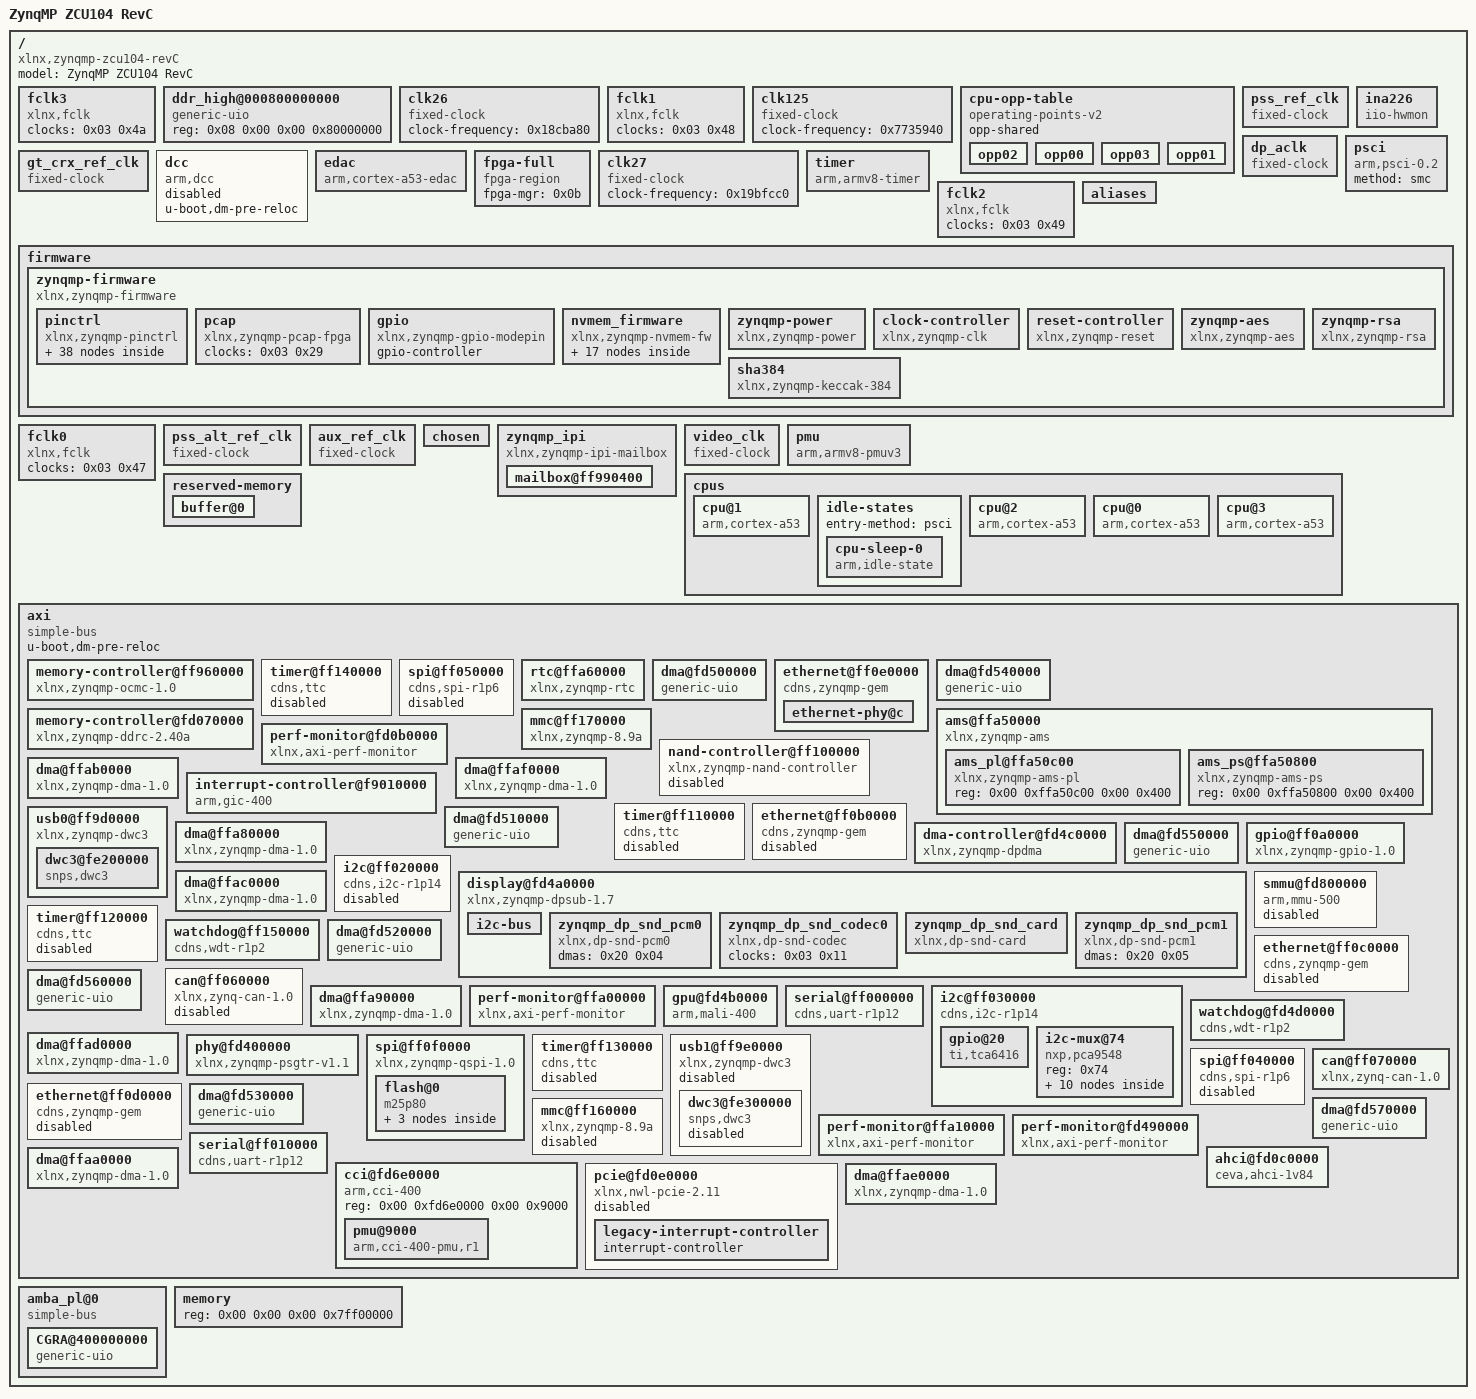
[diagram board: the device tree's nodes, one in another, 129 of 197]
/dts-v1/;

/ {
	#address-cells = <0x02>;
	model = "ZynqMP ZCU104 RevC";
	#size-cells = <0x02>;
	compatible = "xlnx,zynqmp-zcu104-revC\0xlnx,zynqmp-zcu104\0xlnx,zynqmp";

	fclk3 {
		clocks = <0x03 0x4a>;
		compatible = "xlnx,fclk";
		status = "okay";
		phandle = <0x85>;
	};

	ddr_high@000800000000 {
		compatible = "generic-uio";
		reg = <0x08 0x00 0x00 0x80000000>;
	};

	clk26 {
		#clock-cells = <0x00>;
		clock-frequency = <0x18cba80>;
		compatible = "fixed-clock";
		phandle = <0x17>;
	};

	fclk1 {
		clocks = <0x03 0x48>;
		compatible = "xlnx,fclk";
		status = "okay";
		phandle = <0x83>;
	};

	clk125 {
		#clock-cells = <0x00>;
		clock-frequency = <0x7735940>;
		compatible = "fixed-clock";
		phandle = <0x16>;
	};

	cpu-opp-table {
		opp-shared;
		compatible = "operating-points-v2";
		phandle = <0x01>;

		opp02 {
			opp-microvolt = <0xf4240>;
			opp-hz = <0x00 0x17d783fc>;
			clock-latency-ns = <0x7a120>;
		};

		opp00 {
			opp-microvolt = <0xf4240>;
			opp-hz = <0x00 0x47868bf4>;
			clock-latency-ns = <0x7a120>;
		};

		opp03 {
			opp-microvolt = <0xf4240>;
			opp-hz = <0x00 0x11e1a2fd>;
			clock-latency-ns = <0x7a120>;
		};

		opp01 {
			opp-microvolt = <0xf4240>;
			opp-hz = <0x00 0x23c345fa>;
			clock-latency-ns = <0x7a120>;
		};
	};

	pss_ref_clk {
		u-boot,dm-pre-reloc;
		#clock-cells = <0x00>;
		clock-frequency = <0x1fca055>;
		compatible = "fixed-clock";
		phandle = <0x06>;
	};

	ina226 {
		io-channels = <0x25 0x00 0x25 0x01 0x25 0x02 0x25 0x03>;
		compatible = "iio-hwmon";
	};

	dp_aclk {
		clock-accuracy = <0x64>;
		#clock-cells = <0x00>;
		clock-frequency = <0x5f5e100>;
		compatible = "fixed-clock";
		phandle = <0x21>;
	};

	gt_crx_ref_clk {
		u-boot,dm-pre-reloc;
		#clock-cells = <0x00>;
		clock-frequency = <0x66ff300>;
		compatible = "fixed-clock";
		phandle = <0x0a>;
	};

	psci {
		method = "smc";
		compatible = "arm,psci-0.2";
	};

	dcc {
		u-boot,dm-pre-reloc;
		compatible = "arm,dcc";
		status = "disabled";
		phandle = <0x2b>;
	};

	edac {
		compatible = "arm,cortex-a53-edac";
	};

	fpga-full {
		fpga-mgr = <0x0b>;
		#address-cells = <0x02>;
		#size-cells = <0x02>;
		compatible = "fpga-region";
		ranges;
		phandle = <0x42>;
	};

	clk27 {
		#clock-cells = <0x00>;
		clock-frequency = <0x19bfcc0>;
		compatible = "fixed-clock";
		phandle = <0x18>;
	};

	timer {
		interrupts = <0x01 0x0d 0xf08 0x01 0x0e 0xf08 0x01 0x0b 0xf08 0x01 0x0a 0xf08>;
		interrupt-parent = <0x04>;
		compatible = "arm,armv8-timer";
	};

	fclk2 {
		clocks = <0x03 0x49>;
		compatible = "xlnx,fclk";
		status = "okay";
		phandle = <0x84>;
	};

	aliases {
		ethernet0 = "/axi/ethernet@ff0e0000";
		spi0 = "/axi/spi@ff0f0000";
		serial1 = "/axi/serial@ff010000";
		i2c0 = "/axi/i2c@ff030000";
		serial0 = "/axi/serial@ff000000";
	};

	firmware {

		zynqmp-firmware {
			method = "smc";
			u-boot,dm-pre-reloc;
			#power-domain-cells = <0x01>;
			compatible = "xlnx,zynqmp-firmware";
			phandle = <0x0c>;

			pinctrl {
				compatible = "xlnx,zynqmp-pinctrl";
				status = "okay";
				phandle = <0x3f>;

				usb0-default {
					phandle = <0x1f>;

					mux {
						function = "usb0";
						groups = "usb0_0_grp";
					};

					conf {
						drive-strength = <0x0c>;
						slew-rate = <0x01>;
						groups = "usb0_0_grp";
						power-source = <0x01>;
					};

					conf-tx {
						pins = "MIO54\0MIO56\0MIO57\0MIO58\0MIO59\0MIO60\0MIO61\0MIO62\0MIO63";
						bias-disable;
					};

					conf-rx {
						pins = "MIO52\0MIO53\0MIO55";
						bias-high-impedance;
					};
				};

				sdhci1-default {
					phandle = <0x1b>;

					mux-cd {
						function = "sdio1_cd";
						groups = "sdio1_cd_0_grp";
					};

					conf-cd {
						bias-high-impedance;
						slew-rate = <0x01>;
						bias-pull-up;
						groups = "sdio1_cd_0_grp";
						power-source = <0x01>;
					};

					mux {
						function = "sdio1";
						groups = "sdio1_0_grp";
					};

					conf {
						drive-strength = <0x0c>;
						bias-disable;
						slew-rate = <0x01>;
						groups = "sdio1_0_grp";
						power-source = <0x01>;
					};
				};

				i2c1-default {
					phandle = <0x11>;

					mux {
						function = "i2c1";
						groups = "i2c1_4_grp";
					};

					conf {
						drive-strength = <0x0c>;
						slew-rate = <0x01>;
						bias-pull-up;
						groups = "i2c1_4_grp";
						power-source = <0x01>;
					};
				};

				uart1-default {
					phandle = <0x1d>;

					mux {
						function = "uart1";
						groups = "uart1_5_grp";
					};

					conf {
						drive-strength = <0x0c>;
						slew-rate = <0x01>;
						groups = "uart1_5_grp";
						power-source = <0x01>;
					};

					conf-tx {
						pins = "MIO20";
						bias-disable;
					};

					conf-rx {
						pins = "MIO21";
						bias-high-impedance;
					};
				};

				can1-default {
					phandle = <0x0d>;

					mux {
						function = "can1";
						groups = "can1_6_grp";
					};

					conf {
						drive-strength = <0x0c>;
						slew-rate = <0x01>;
						groups = "can1_6_grp";
						power-source = <0x01>;
					};

					conf-tx {
						pins = "MIO24";
						bias-disable;
					};

					conf-rx {
						pins = "MIO25";
						bias-high-impedance;
					};
				};

				i2c1-gpio {
					phandle = <0x12>;

					mux {
						function = "gpio0";
						groups = "gpio0_16_grp\0gpio0_17_grp";
					};

					conf {
						drive-strength = <0x0c>;
						slew-rate = <0x01>;
						groups = "gpio0_16_grp\0gpio0_17_grp";
						power-source = <0x01>;
					};
				};

				gem3-default {
					phandle = <0x10>;

					mux {
						function = "ethernet3";
						groups = "ethernet3_0_grp";
					};

					conf {
						drive-strength = <0x0c>;
						slew-rate = <0x01>;
						groups = "ethernet3_0_grp";
						power-source = <0x01>;
					};

					mux-mdio {
						function = "mdio3";
						groups = "mdio3_0_grp";
					};

					conf-mdio {
						bias-disable;
						slew-rate = <0x01>;
						groups = "mdio3_0_grp";
						power-source = <0x01>;
					};

					conf-tx {
						pins = "MIO64\0MIO65\0MIO66\0MIO67\0MIO68\0MIO69";
						bias-disable;
						low-power-enable;
					};

					conf-rx {
						low-power-disable;
						pins = "MIO70\0MIO71\0MIO72\0MIO73\0MIO74\0MIO75";
						bias-high-impedance;
					};
				};

				uart0-default {
					phandle = <0x1c>;

					mux {
						function = "uart0";
						groups = "uart0_4_grp";
					};

					conf {
						drive-strength = <0x0c>;
						slew-rate = <0x01>;
						groups = "uart0_4_grp";
						power-source = <0x01>;
					};

					conf-tx {
						pins = "MIO19";
						bias-disable;
					};

					conf-rx {
						pins = "MIO18";
						bias-high-impedance;
					};
				};
			};

			pcap {
				clock-names = "ref_clk";
				clocks = <0x03 0x29>;
				compatible = "xlnx,zynqmp-pcap-fpga";
				phandle = <0x0b>;
			};

			gpio {
				gpio-controller;
				compatible = "xlnx,zynqmp-gpio-modepin";
				phandle = <0x1e>;
				#gpio-cells = <0x02>;
			};

			nvmem_firmware {
				#address-cells = <0x01>;
				#size-cells = <0x01>;
				compatible = "xlnx,zynqmp-nvmem-fw";

				efuse_pufmisc@54 {
					reg = <0x54 0x04>;
					phandle = <0x39>;
				};

				efuse_ppk1hash@d0 {
					reg = <0xd0 0x30>;
					phandle = <0x3d>;
				};

				efuse_usr3@2c {
					reg = <0x2c 0x04>;
					phandle = <0x32>;
				};

				efuse_dna@c {
					reg = <0x0c 0x0c>;
					phandle = <0x2e>;
				};

				efuse_ppk0hash@a0 {
					reg = <0xa0 0x30>;
					phandle = <0x3c>;
				};

				efuse_usr1@24 {
					reg = <0x24 0x04>;
					phandle = <0x30>;
				};

				efuse_usr6@38 {
					reg = <0x38 0x04>;
					phandle = <0x35>;
				};

				efuse_spkid@5c {
					reg = <0x5c 0x04>;
					phandle = <0x3b>;
				};

				efuse_chash@50 {
					reg = <0x50 0x04>;
					phandle = <0x38>;
				};

				efuse_usr4@30 {
					reg = <0x30 0x04>;
					phandle = <0x33>;
				};

				efuse_miscusr@40 {
					reg = <0x40 0x04>;
					phandle = <0x37>;
				};

				efuse_usr7@3c {
					reg = <0x3c 0x04>;
					phandle = <0x36>;
				};

				efuse_usr2@28 {
					reg = <0x28 0x04>;
					phandle = <0x31>;
				};

				efuse_usr0@20 {
					reg = <0x20 0x04>;
					phandle = <0x2f>;
				};

				soc_revision@0 {
					reg = <0x00 0x04>;
					phandle = <0x2d>;
				};

				efuse_sec@58 {
					reg = <0x58 0x04>;
					phandle = <0x3a>;
				};

				efuse_usr5@34 {
					reg = <0x34 0x04>;
					phandle = <0x34>;
				};
			};

			zynqmp-power {
				u-boot,dm-pre-reloc;
				interrupts = <0x00 0x23 0x04>;
				interrupt-parent = <0x04>;
				compatible = "xlnx,zynqmp-power";
				phandle = <0x2c>;
				mboxes = <0x05 0x00 0x05 0x01>;
				mbox-names = "tx\0rx";
			};

			clock-controller {
				clock-names = "pss_ref_clk\0video_clk\0pss_alt_ref_clk\0aux_ref_clk\0gt_crx_ref_clk";
				u-boot,dm-pre-reloc;
				clocks = <0x06 0x07 0x08 0x09 0x0a>;
				#clock-cells = <0x01>;
				compatible = "xlnx,zynqmp-clk";
				phandle = <0x03>;
			};

			reset-controller {
				#reset-cells = <0x01>;
				compatible = "xlnx,zynqmp-reset";
				phandle = <0x19>;
			};

			zynqmp-aes {
				compatible = "xlnx,zynqmp-aes";
				phandle = <0x3e>;
			};

			sha384 {
				compatible = "xlnx,zynqmp-keccak-384";
				phandle = <0x40>;
			};

			zynqmp-rsa {
				compatible = "xlnx,zynqmp-rsa";
				phandle = <0x41>;
			};
		};
	};

	fclk0 {
		clocks = <0x03 0x47>;
		compatible = "xlnx,fclk";
		status = "okay";
		phandle = <0x82>;
	};

	pss_alt_ref_clk {
		u-boot,dm-pre-reloc;
		#clock-cells = <0x00>;
		clock-frequency = <0x00>;
		compatible = "fixed-clock";
		phandle = <0x08>;
	};

	aux_ref_clk {
		u-boot,dm-pre-reloc;
		#clock-cells = <0x00>;
		clock-frequency = <0x19bfcc0>;
		compatible = "fixed-clock";
		phandle = <0x09>;
	};

	chosen {
		bootargs = "earlycon clk_ignore_unused cpuidle.off=1 root=/dev/mmcblk0p2 rw rootwait uio_pdrv_genirq.of_id=generic-uio mem=1792M";
		nvmem0 = "/axi/i2c@ff030000/i2c-mux@74/i2c@0/eeprom@54";
		stdout-path = "serial0:115200n8";
	};

	zynqmp_ipi {
		#address-cells = <0x02>;
		xlnx,ipi-id = <0x00>;
		u-boot,dm-pre-reloc;
		interrupts = <0x00 0x23 0x04>;
		#size-cells = <0x02>;
		interrupt-parent = <0x04>;
		compatible = "xlnx,zynqmp-ipi-mailbox";
		ranges;
		phandle = <0x2a>;

		mailbox@ff990400 {
			xlnx,ipi-id = <0x04>;
			reg-names = "local_request_region\0local_response_region\0remote_request_region\0remote_response_region";
			u-boot,dm-pre-reloc;
			#mbox-cells = <0x01>;
			reg = <0x00 0xff9905c0 0x00 0x20 0x00 0xff9905e0 0x00 0x20 0x00 0xff990e80 0x00 0x20 0x00 0xff990ea0 0x00 0x20>;
			phandle = <0x05>;
		};
	};

	video_clk {
		u-boot,dm-pre-reloc;
		#clock-cells = <0x00>;
		clock-frequency = <0x1fc9f08>;
		compatible = "fixed-clock";
		phandle = <0x07>;
	};

	pmu {
		interrupts = <0x00 0x8f 0x04 0x00 0x90 0x04 0x00 0x91 0x04 0x00 0x92 0x04>;
		interrupt-parent = <0x04>;
		compatible = "arm,armv8-pmuv3";
	};

	cpus {
		#address-cells = <0x01>;
		#size-cells = <0x00>;

		cpu@1 {
			cpu-idle-states = <0x02>;
			device_type = "cpu";
			compatible = "arm,cortex-a53";
			reg = <0x01>;
			enable-method = "psci";
			phandle = <0x27>;
			operating-points-v2 = <0x01>;
		};

		idle-states {
			entry-method = "psci";

			cpu-sleep-0 {
				entry-latency-us = <0x12c>;
				local-timer-stop;
				exit-latency-us = <0x258>;
				arm,psci-suspend-param = <0x40000000>;
				compatible = "arm,idle-state";
				phandle = <0x02>;
				min-residency-us = <0x2710>;
			};
		};

		cpu@2 {
			cpu-idle-states = <0x02>;
			device_type = "cpu";
			compatible = "arm,cortex-a53";
			reg = <0x02>;
			enable-method = "psci";
			phandle = <0x28>;
			operating-points-v2 = <0x01>;
		};

		cpu@0 {
			clocks = <0x03 0x0a>;
			cpu-idle-states = <0x02>;
			device_type = "cpu";
			compatible = "arm,cortex-a53";
			reg = <0x00>;
			enable-method = "psci";
			phandle = <0x26>;
			operating-points-v2 = <0x01>;
		};

		cpu@3 {
			cpu-idle-states = <0x02>;
			device_type = "cpu";
			compatible = "arm,cortex-a53";
			reg = <0x03>;
			enable-method = "psci";
			phandle = <0x29>;
			operating-points-v2 = <0x01>;
		};
	};

	__symbols__ {
		efuse_usr0 = "/firmware/zynqmp-firmware/nvmem_firmware/efuse_usr0@20";
		fpd_dma_chan3 = "/axi/dma@fd520000";
		efuse_ppk0hash = "/firmware/zynqmp-firmware/nvmem_firmware/efuse_ppk0hash@a0";
		ams_ps = "/axi/ams@ffa50000/ams_ps@ffa50800";
		nand0 = "/axi/nand-controller@ff100000";
		fclk3 = "/fclk3";
		zynqmp_pcap = "/firmware/zynqmp-firmware/pcap";
		reserved = "/reserved-memory/buffer@0";
		CPU_SLEEP_0 = "/cpus/idle-states/cpu-sleep-0";
		pinctrl_uart0_default = "/firmware/zynqmp-firmware/pinctrl/uart0-default";
		efuse_chash = "/firmware/zynqmp-firmware/nvmem_firmware/efuse_chash@50";
		ipi_mailbox_pmu1 = "/zynqmp_ipi/mailbox@ff990400";
		i2c1 = "/axi/i2c@ff030000";
		fpd_dma_chan1 = "/axi/dma@fd500000";
		efuse_sec = "/firmware/zynqmp-firmware/nvmem_firmware/efuse_sec@58";
		pinctrl_sdhci1_default = "/firmware/zynqmp-firmware/pinctrl/sdhci1-default";
		ttc3 = "/axi/timer@ff140000";
		qspi = "/axi/spi@ff0f0000";
		zynqmp_dp_snd_pcm0 = "/axi/display@fd4a0000/zynqmp_dp_snd_pcm0";
		fclk1 = "/fclk1";
		gpu = "/axi/gpu@fd4b0000";
		spi0 = "/axi/spi@ff040000";
		lpd_dma_chan8 = "/axi/dma@ffaf0000";
		pinctrl_i2c1_default = "/firmware/zynqmp-firmware/pinctrl/i2c1-default";
		efuse_usr7 = "/firmware/zynqmp-firmware/nvmem_firmware/efuse_usr7@3c";
		gpio = "/axi/gpio@ff0a0000";
		zynqmp_clk = "/firmware/zynqmp-firmware/clock-controller";
		usb1 = "/axi/usb1@ff9e0000";
		ttc1 = "/axi/timer@ff120000";
		amba = "/axi";
		efuse_spkid = "/firmware/zynqmp-firmware/nvmem_firmware/efuse_spkid@5c";
		pss_ref_clk = "/pss_ref_clk";
		lpd_dma_chan6 = "/axi/dma@ffad0000";
		efuse_usr5 = "/firmware/zynqmp-firmware/nvmem_firmware/efuse_usr5@34";
		fpd_dma_chan8 = "/axi/dma@fd570000";
		efuse_ppk1hash = "/firmware/zynqmp-firmware/nvmem_firmware/efuse_ppk1hash@d0";
		pinctrl_can1_default = "/firmware/zynqmp-firmware/pinctrl/can1-default";
		CGRA_0 = "/amba_pl@0/CGRA@400000000";
		gem3 = "/axi/ethernet@ff0e0000";
		dp_aclk = "/dp_aclk";
		cpu3 = "/cpus/cpu@3";
		dwc3_0 = "/axi/usb0@ff9d0000/dwc3@fe200000";
		perf_monitor_cci = "/axi/perf-monitor@fd490000";
		clock_8t49n287_2 = "/clk26";
		lpd_dma_chan4 = "/axi/dma@ffab0000";
		efuse_usr3 = "/firmware/zynqmp-firmware/nvmem_firmware/efuse_usr3@2c";
		fpd_dma_chan6 = "/axi/dma@fd550000";
		gt_crx_ref_clk = "/gt_crx_ref_clk";
		gic = "/axi/interrupt-controller@f9010000";
		gem1 = "/axi/ethernet@ff0c0000";
		sata = "/axi/ahci@fd0c0000";
		cpu1 = "/cpus/cpu@1";
		xilinx_ams = "/axi/ams@ffa50000";
		pinctrl_gem3_default = "/firmware/zynqmp-firmware/pinctrl/gem3-default";
		perf_monitor_lpd = "/axi/perf-monitor@ffa10000";
		xlnx_keccak_384 = "/firmware/zynqmp-firmware/sha384";
		uart0 = "/axi/serial@ff000000";
		zynqmp_dp_snd_codec0 = "/axi/display@fd4a0000/zynqmp_dp_snd_codec0";
		dcc = "/dcc";
		lpd_dma_chan2 = "/axi/dma@ffa90000";
		ams_pl = "/axi/ams@ffa50000/ams_pl@ffa50c00";
		efuse_usr1 = "/firmware/zynqmp-firmware/nvmem_firmware/efuse_usr1@24";
		fpd_dma_chan4 = "/axi/dma@fd530000";
		cci = "/axi/cci@fd6e0000";
		perf_monitor_ddr = "/axi/perf-monitor@fd0b0000";
		cpu_opp_table = "/cpu-opp-table";
		can0 = "/axi/can@ff060000";
		tca6416_u97 = "/axi/i2c@ff030000/gpio@20";
		pcie = "/axi/pcie@fd0e0000";
		sdhci0 = "/axi/mmc@ff160000";
		irps5401_43 = "/axi/i2c@ff030000/i2c-mux@74/i2c@2/irps5401@43";
		perf_monitor_ocm = "/axi/perf-monitor@ffa00000";
		watchdog0 = "/axi/watchdog@fd4d0000";
		fpga_full = "/fpga-full";
		fpd_dma_chan2 = "/axi/dma@fd510000";
		zynqmp_firmware = "/firmware/zynqmp-firmware";
		zynqmp_dp_snd_pcm1 = "/axi/display@fd4a0000/zynqmp_dp_snd_pcm1";
		fclk2 = "/fclk2";
		spi1 = "/axi/spi@ff050000";
		xlnx_aes = "/firmware/zynqmp-firmware/zynqmp-aes";
		ocm = "/axi/memory-controller@ff960000";
		pinctrl_i2c1_gpio = "/firmware/zynqmp-firmware/pinctrl/i2c1-gpio";
		eeprom = "/axi/i2c@ff030000/i2c-mux@74/i2c@0/eeprom@54";
		pinctrl_uart1_default = "/firmware/zynqmp-firmware/pinctrl/uart1-default";
		i2c0 = "/axi/i2c@ff020000";
		ttc2 = "/axi/timer@ff130000";
		soc_revision = "/firmware/zynqmp-firmware/nvmem_firmware/soc_revision@0";
		fclk0 = "/fclk0";
		clock_8t49n287_5 = "/clk125";
		pss_alt_ref_clk = "/pss_alt_ref_clk";
		lpd_dma_chan7 = "/axi/dma@ffae0000";
		efuse_usr6 = "/firmware/zynqmp-firmware/nvmem_firmware/efuse_usr6@38";
		efuse_dna = "/firmware/zynqmp-firmware/nvmem_firmware/efuse_dna@c";
		aux_ref_clk = "/aux_ref_clk";
		psgtr = "/axi/phy@fd400000";
		usb0 = "/axi/usb0@ff9d0000";
		amba_pl = "/amba_pl@0";
		xlnx_rsa = "/firmware/zynqmp-firmware/zynqmp-rsa";
		ttc0 = "/axi/timer@ff110000";
		flash0 = "/axi/spi@ff0f0000/flash@0";
		mc = "/axi/memory-controller@fd070000";
		zynqmp_dpsub = "/axi/display@fd4a0000";
		pinctrl0 = "/firmware/zynqmp-firmware/pinctrl";
		dwc3_1 = "/axi/usb1@ff9e0000/dwc3@fe300000";
		clock_8t49n287_3 = "/clk27";
		phy0 = "/axi/ethernet@ff0e0000/ethernet-phy@c";
		lpd_dma_chan5 = "/axi/dma@ffac0000";
		zynqmp_ipi = "/zynqmp_ipi";
		efuse_usr4 = "/firmware/zynqmp-firmware/nvmem_firmware/efuse_usr4@30";
		fpd_dma_chan7 = "/axi/dma@fd560000";
		video_clk = "/video_clk";
		u183 = "/axi/i2c@ff030000/i2c-mux@74/i2c@3/ina226@40";
		gem2 = "/axi/ethernet@ff0d0000";
		efuse_pufmisc = "/firmware/zynqmp-firmware/nvmem_firmware/efuse_pufmisc@54";
		zynqmp_dpdma = "/axi/dma-controller@fd4c0000";
		cpu2 = "/cpus/cpu@2";
		uart1 = "/axi/serial@ff010000";
		efuse_miscusr = "/firmware/zynqmp-firmware/nvmem_firmware/efuse_miscusr@40";
		lpd_dma_chan3 = "/axi/dma@ffaa0000";
		efuse_usr2 = "/firmware/zynqmp-firmware/nvmem_firmware/efuse_usr2@28";
		fpd_dma_chan5 = "/axi/dma@fd540000";
		zynqmp_dp_snd_card0 = "/axi/display@fd4a0000/zynqmp_dp_snd_card";
		zynqmp_power = "/firmware/zynqmp-firmware/zynqmp-power";
		can1 = "/axi/can@ff070000";
		gem0 = "/axi/ethernet@ff0b0000";
		pinctrl_usb0_default = "/firmware/zynqmp-firmware/pinctrl/usb0-default";
		pcie_intc = "/axi/pcie@fd0e0000/legacy-interrupt-controller";
		sdhci1 = "/axi/mmc@ff170000";
		irps5401_44 = "/axi/i2c@ff030000/i2c-mux@74/i2c@2/irps5401@44";
		rtc = "/axi/rtc@ffa60000";
		smmu = "/axi/smmu@fd800000";
		lpd_watchdog = "/axi/watchdog@ff150000";
		modepin_gpio = "/firmware/zynqmp-firmware/gpio";
		cpu0 = "/cpus/cpu@0";
		zynqmp_reset = "/firmware/zynqmp-firmware/reset-controller";
		lpd_dma_chan1 = "/axi/dma@ffa80000";
	};

	reserved-memory {
		#address-cells = <0x02>;
		#size-cells = <0x02>;
		ranges;

		buffer@0 {
			reg = <0x08 0x00 0x00 0x80000000>;
			phandle = <0x88>;
			no-map;
		};
	};

	axi {
		#address-cells = <0x02>;
		u-boot,dm-pre-reloc;
		#size-cells = <0x02>;
		compatible = "simple-bus";
		ranges;
		phandle = <0x43>;

		memory-controller@ff960000 {
			interrupts = <0x00 0x0a 0x04>;
			interrupt-parent = <0x04>;
			compatible = "xlnx,zynqmp-ocmc-1.0";
			reg = <0x00 0xff960000 0x00 0x1000>;
			phandle = <0x64>;
		};

		timer@ff140000 {
			power-domains = <0x0c 0x1b>;
			timer-width = <0x20>;
			interrupts = <0x00 0x2d 0x04 0x00 0x2e 0x04 0x00 0x2f 0x04>;
			clocks = <0x03 0x1f>;
			interrupt-parent = <0x04>;
			compatible = "cdns,ttc";
			status = "disabled";
			reg = <0x00 0xff140000 0x00 0x1000>;
			phandle = <0x74>;
		};

		spi@ff050000 {
			power-domains = <0x0c 0x24>;
			#address-cells = <0x01>;
			clock-names = "ref_clk\0pclk";
			interrupts = <0x00 0x14 0x04>;
			clocks = <0x03 0x3b 0x03 0x1f>;
			#size-cells = <0x00>;
			interrupt-parent = <0x04>;
			compatible = "cdns,spi-r1p6";
			status = "disabled";
			reg = <0x00 0xff050000 0x00 0x1000>;
			phandle = <0x70>;
		};

		rtc@ffa60000 {
			calibration = <0x7fff>;
			interrupts = <0x00 0x1a 0x04 0x00 0x1b 0x04>;
			interrupt-parent = <0x04>;
			compatible = "xlnx,zynqmp-rtc";
			status = "okay";
			interrupt-names = "alarm\0sec";
			reg = <0x00 0xffa60000 0x00 0x100>;
			phandle = <0x6b>;
		};

		dma@fd500000 {
			power-domains = <0x0c 0x2a>;
			iommus = <0x0e 0x14e8>;
			clock-names = "clk_main\0clk_apb";
			interrupts = <0x00 0x7c 0x04>;
			clocks = <0x03 0x13 0x03 0x1f>;
			interrupt-parent = <0x04>;
			xlnx,bus-width = <0x80>;
			compatible = "generic-uio";
			status = "okay";
			#stream-id-cells = <0x01>;
			reg = <0x00 0xfd500000 0x00 0x1000>;
			phandle = <0x47>;
		};

		ethernet@ff0e0000 {
			power-domains = <0x0c 0x20>;
			iommus = <0x0e 0x877>;
			pinctrl-names = "default";
			#address-cells = <0x01>;
			phy-mode = "rgmii-id";
			pinctrl-0 = <0x10>;
			clock-names = "pclk\0hclk\0tx_clk\0rx_clk\0tsu_clk";
			local-mac-address = [00 0a 35 00 9b 24];
			interrupts = <0x00 0x3f 0x04 0x00 0x3f 0x04>;
			clocks = <0x03 0x1f 0x03 0x6b 0x03 0x30 0x03 0x34 0x03 0x2c>;
			#size-cells = <0x00>;
			interrupt-parent = <0x04>;
			compatible = "cdns,zynqmp-gem\0cdns,gem";
			status = "okay";
			#stream-id-cells = <0x01>;
			reg = <0x00 0xff0e0000 0x00 0x1000>;
			phandle = <0x5d>;
			phy-handle = <0x0f>;
			xlnx,ptp-enet-clock = <0x00>;

			ethernet-phy@c {
				ti,dp83867-rxctrl-strap-quirk;
				ti,tx-internal-delay = <0x0a>;
				ti,fifo-depth = <0x01>;
				ti,rx-internal-delay = <0x08>;
				reg = <0x0c>;
				phandle = <0x0f>;
			};
		};

		dma@fd540000 {
			power-domains = <0x0c 0x2a>;
			iommus = <0x0e 0x14ec>;
			clock-names = "clk_main\0clk_apb";
			interrupts = <0x00 0x80 0x04>;
			clocks = <0x03 0x13 0x03 0x1f>;
			interrupt-parent = <0x04>;
			xlnx,bus-width = <0x80>;
			compatible = "generic-uio";
			status = "okay";
			#stream-id-cells = <0x01>;
			reg = <0x00 0xfd540000 0x00 0x1000>;
			phandle = <0x4b>;
		};

		ams@ffa50000 {
			#address-cells = <0x02>;
			reg-names = "ams-base";
			interrupts = <0x00 0x38 0x04>;
			clocks = <0x03 0x46>;
			#io-channel-cells = <0x01>;
			#size-cells = <0x02>;
			interrupt-parent = <0x04>;
			compatible = "xlnx,zynqmp-ams";
			ranges;
			status = "okay";
			interrupt-names = "ams-irq";
			reg = <0x00 0xffa50000 0x00 0x800>;
			phandle = <0x7d>;

			ams_pl@ffa50c00 {
				compatible = "xlnx,zynqmp-ams-pl";
				status = "okay";
				reg = <0x00 0xffa50c00 0x00 0x400>;
				phandle = <0x7f>;
			};

			ams_ps@ffa50800 {
				compatible = "xlnx,zynqmp-ams-ps";
				status = "okay";
				reg = <0x00 0xffa50800 0x00 0x400>;
				phandle = <0x7e>;
			};
		};

		memory-controller@fd070000 {
			interrupts = <0x00 0x70 0x04>;
			interrupt-parent = <0x04>;
			compatible = "xlnx,zynqmp-ddrc-2.40a";
			reg = <0x00 0xfd070000 0x00 0x30000>;
			phandle = <0x58>;
		};

		mmc@ff170000 {
			power-domains = <0x0c 0x28>;
			iommus = <0x0e 0x871>;
			pinctrl-names = "default";
			clock-output-names = "clk_out_sd1\0clk_in_sd1";
			xlnx,mio-bank = <0x01>;
			pinctrl-0 = <0x1b>;
			clock-names = "clk_xin\0clk_ahb";
			u-boot,dm-pre-reloc;
			interrupts = <0x00 0x31 0x04>;
			clocks = <0x03 0x37 0x03 0x1f>;
			#clock-cells = <0x01>;
			xlnx,device_id = <0x01>;
			interrupt-parent = <0x04>;
			clock-frequency = <0xb2d05e0>;
			no-1-8-v;
			compatible = "xlnx,zynqmp-8.9a\0arasan,sdhci-8.9a";
			status = "okay";
			disable-wp;
			#stream-id-cells = <0x01>;
			reg = <0x00 0xff170000 0x00 0x1000>;
			phandle = <0x6e>;
		};

		perf-monitor@fd0b0000 {
			xlnx,metric-count-width = <0x20>;
			xlnx,have-sampled-metric-cnt = <0x01>;
			xlnx,enable-trace = <0x00>;
			xlnx,global-count-width = <0x20>;
			xlnx,enable-event-count = <0x01>;
			interrupts = <0x00 0x7b 0x04>;
			clocks = <0x03 0x1c>;
			xlnx,enable-profile = <0x00>;
			xlnx,metric-count-scale = <0x01>;
			interrupt-parent = <0x04>;
			xlnx,num-monitor-slots = <0x06>;
			compatible = "xlnx,axi-perf-monitor";
			xlnx,num-of-counters = <0x0a>;
			reg = <0x00 0xfd0b0000 0x00 0x10000>;
			phandle = <0x66>;
			xlnx,metrics-sample-count-width = <0x20>;
			xlnx,enable-event-log = <0x00>;
		};

		nand-controller@ff100000 {
			power-domains = <0x0c 0x2c>;
			iommus = <0x0e 0x872>;
			#address-cells = <0x01>;
			clock-names = "controller\0bus";
			interrupts = <0x00 0x0e 0x04>;
			clocks = <0x03 0x3c 0x03 0x1f>;
			#size-cells = <0x00>;
			interrupt-parent = <0x04>;
			compatible = "xlnx,zynqmp-nand-controller\0arasan,nfc-v3p10";
			status = "disabled";
			#stream-id-cells = <0x01>;
			reg = <0x00 0xff100000 0x00 0x1000>;
			phandle = <0x59>;
		};

		dma@ffab0000 {
			power-domains = <0x0c 0x2b>;
			clock-names = "clk_main\0clk_apb";
			interrupts = <0x00 0x50 0x04>;
			clocks = <0x03 0x44 0x03 0x1f>;
			interrupt-parent = <0x04>;
			xlnx,bus-width = <0x40>;
			compatible = "xlnx,zynqmp-dma-1.0";
			status = "okay";
			#stream-id-cells = <0x01>;
			reg = <0x00 0xffab0000 0x00 0x1000>;
			phandle = <0x53>;
		};

		interrupt-controller@f9010000 {
			num_cpus = <0x02>;
			interrupts = <0x01 0x09 0xf04>;
			interrupt-parent = <0x04>;
			compatible = "arm,gic-400";
			#interrupt-cells = <0x03>;
			num_interrupts = <0x60>;
			reg = <0x00 0xf9010000 0x00 0x10000 0x00 0xf9020000 0x00 0x20000 0x00 0xf9040000 0x00 0x20000 0x00 0xf9060000 0x00 0x20000>;
			phandle = <0x04>;
			interrupt-controller;
		};

		dma@ffaf0000 {
			power-domains = <0x0c 0x2b>;
			clock-names = "clk_main\0clk_apb";
			interrupts = <0x00 0x54 0x04>;
			clocks = <0x03 0x44 0x03 0x1f>;
			interrupt-parent = <0x04>;
			xlnx,bus-width = <0x40>;
			compatible = "xlnx,zynqmp-dma-1.0";
			status = "okay";
			#stream-id-cells = <0x01>;
			reg = <0x00 0xffaf0000 0x00 0x1000>;
			phandle = <0x57>;
		};

		timer@ff110000 {
			power-domains = <0x0c 0x18>;
			timer-width = <0x20>;
			interrupts = <0x00 0x24 0x04 0x00 0x25 0x04 0x00 0x26 0x04>;
			clocks = <0x03 0x1f>;
			interrupt-parent = <0x04>;
			compatible = "cdns,ttc";
			status = "disabled";
			reg = <0x00 0xff110000 0x00 0x1000>;
			phandle = <0x71>;
		};

		ethernet@ff0b0000 {
			power-domains = <0x0c 0x1d>;
			iommus = <0x0e 0x874>;
			#address-cells = <0x01>;
			clock-names = "pclk\0hclk\0tx_clk\0rx_clk\0tsu_clk";
			interrupts = <0x00 0x39 0x04 0x00 0x39 0x04>;
			clocks = <0x03 0x1f 0x03 0x68 0x03 0x2d 0x03 0x31 0x03 0x2c>;
			#size-cells = <0x00>;
			interrupt-parent = <0x04>;
			compatible = "cdns,zynqmp-gem\0cdns,gem";
			status = "disabled";
			#stream-id-cells = <0x01>;
			reg = <0x00 0xff0b0000 0x00 0x1000>;
			phandle = <0x5a>;
		};

		usb0@ff9d0000 {
			power-domains = <0x0c 0x16>;
			xlnx,tz-nonsecure = <0x01>;
			pinctrl-names = "default";
			#address-cells = <0x02>;
			xlnx,usb-reset-mode = <0x00>;
			phy-names = "usb3-phy";
			pinctrl-0 = <0x1f>;
			clock-names = "bus_clk\0ref_clk";
			resets = <0x19 0x3b 0x19 0x3d 0x19 0x3f>;
			clocks = <0x03 0x20 0x03 0x22>;
			#size-cells = <0x02>;
			xlnx,usb-polarity = <0x00>;
			reset-gpio = <0x1e 0x01 0x00>;
			compatible = "xlnx,zynqmp-dwc3";
			ranges;
			status = "okay";
			phys = <0x1a 0x02 0x04 0x00 0x02>;
			reg = <0x00 0xff9d0000 0x00 0x100>;
			phandle = <0x77>;
			reset-names = "usb_crst\0usb_hibrst\0usb_apbrst";

			dwc3@fe200000 {
				iommus = <0x0e 0x860>;
				snps,quirk-frame-length-adjustment = <0x20>;
				snps,usb3_lpm_capable;
				snps,refclk_fladj;
				interrupts = <0x00 0x41 0x04 0x00 0x45 0x04 0x00 0x4b 0x04>;
				interrupt-parent = <0x04>;
				compatible = "snps,dwc3";
				status = "okay";
				interrupt-names = "dwc_usb3\0otg\0hiber";
				snps,enable_guctl1_ipd_quirk;
				#stream-id-cells = <0x01>;
				snps,xhci-stream-quirk;
				reg = <0x00 0xfe200000 0x00 0x40000>;
				phandle = <0x78>;
				dr_mode = "host";
				maximum-speed = "super-speed";
				snps,enable_guctl1_resume_quirk;
			};
		};

		dma@fd510000 {
			power-domains = <0x0c 0x2a>;
			iommus = <0x0e 0x14e9>;
			clock-names = "clk_main\0clk_apb";
			interrupts = <0x00 0x7d 0x04>;
			clocks = <0x03 0x13 0x03 0x1f>;
			interrupt-parent = <0x04>;
			xlnx,bus-width = <0x80>;
			compatible = "generic-uio";
			status = "okay";
			#stream-id-cells = <0x01>;
			reg = <0x00 0xfd510000 0x00 0x1000>;
			phandle = <0x48>;
		};

		dma@ffa80000 {
			power-domains = <0x0c 0x2b>;
			clock-names = "clk_main\0clk_apb";
			interrupts = <0x00 0x4d 0x04>;
			clocks = <0x03 0x44 0x03 0x1f>;
			interrupt-parent = <0x04>;
			xlnx,bus-width = <0x40>;
			compatible = "xlnx,zynqmp-dma-1.0";
			status = "okay";
			#stream-id-cells = <0x01>;
			reg = <0x00 0xffa80000 0x00 0x1000>;
			phandle = <0x50>;
		};

		dma-controller@fd4c0000 {
			power-domains = <0x0c 0x29>;
			iommus = <0x0e 0xce4>;
			clock-names = "axi_clk";
			interrupts = <0x00 0x7a 0x04>;
			clocks = <0x03 0x14>;
			interrupt-parent = <0x04>;
			compatible = "xlnx,zynqmp-dpdma";
			status = "okay";
			#stream-id-cells = <0x01>;
			reg = <0x00 0xfd4c0000 0x00 0x1000>;
			phandle = <0x20>;
			dma-channels = <0x06>;
			#dma-cells = <0x01>;
		};

		dma@fd550000 {
			power-domains = <0x0c 0x2a>;
			iommus = <0x0e 0x14ed>;
			clock-names = "clk_main\0clk_apb";
			interrupts = <0x00 0x81 0x04>;
			clocks = <0x03 0x13 0x03 0x1f>;
			interrupt-parent = <0x04>;
			xlnx,bus-width = <0x80>;
			compatible = "generic-uio";
			status = "okay";
			#stream-id-cells = <0x01>;
			reg = <0x00 0xfd550000 0x00 0x1000>;
			phandle = <0x4c>;
		};

		gpio@ff0a0000 {
			power-domains = <0x0c 0x2e>;
			gpio-mask-low = <0x5600>;
			gpio-controller;
			interrupts = <0x00 0x10 0x04>;
			clocks = <0x03 0x1f>;
			gpio-mask-high = <0x00>;
			interrupt-parent = <0x04>;
			compatible = "xlnx,zynqmp-gpio-1.0";
			#interrupt-cells = <0x02>;
			status = "okay";
			reg = <0x00 0xff0a0000 0x00 0x1000>;
			phandle = <0x13>;
			emio-gpio-width = <0x20>;
			#gpio-cells = <0x02>;
			interrupt-controller;
		};

		i2c@ff020000 {
			power-domains = <0x0c 0x25>;
			#address-cells = <0x01>;
			interrupts = <0x00 0x11 0x04>;
			clocks = <0x03 0x3d>;
			#size-cells = <0x00>;
			interrupt-parent = <0x04>;
			compatible = "cdns,i2c-r1p14";
			status = "disabled";
			reg = <0x00 0xff020000 0x00 0x1000>;
			phandle = <0x5e>;
		};

		display@fd4a0000 {
			power-domains = <0x0c 0x29>;
			iommus = <0x0e 0xce3>;
			phy-names = "dp-phy0\0dp-phy1";
			clock-names = "dp_apb_clk\0dp_aud_clk\0dp_vtc_pixel_clk_in";
			reg-names = "dp\0blend\0av_buf\0aud";
			resets = <0x19 0x03>;
			interrupts = <0x00 0x77 0x04>;
			clocks = <0x21 0x03 0x11 0x03 0x10>;
			interrupt-parent = <0x04>;
			dma-names = "vid0\0vid1\0vid2\0gfx0";
			compatible = "xlnx,zynqmp-dpsub-1.7";
			status = "okay";
			phys = <0x1a 0x01 0x06 0x00 0x03 0x1a 0x00 0x06 0x01 0x03>;
			#stream-id-cells = <0x01>;
			reg = <0x00 0xfd4a0000 0x00 0x1000 0x00 0xfd4aa000 0x00 0x1000 0x00 0xfd4ab000 0x00 0x1000 0x00 0xfd4ac000 0x00 0x1000>;
			phandle = <0x80>;
			dmas = <0x20 0x00 0x20 0x01 0x20 0x02 0x20 0x03>;
			xlnx,max-lanes = <0x02>;

			i2c-bus {
			};

			zynqmp_dp_snd_pcm0 {
				dma-names = "tx";
				compatible = "xlnx,dp-snd-pcm0";
				status = "okay";
				phandle = <0x22>;
				dmas = <0x20 0x04>;
			};

			zynqmp_dp_snd_codec0 {
				clock-names = "aud_clk";
				clocks = <0x03 0x11>;
				compatible = "xlnx,dp-snd-codec";
				status = "okay";
				phandle = <0x24>;
			};

			zynqmp_dp_snd_card {
				xlnx,dp-snd-pcm = <0x22 0x23>;
				xlnx,dp-snd-codec = <0x24>;
				compatible = "xlnx,dp-snd-card";
				status = "okay";
				phandle = <0x81>;
			};

			zynqmp_dp_snd_pcm1 {
				dma-names = "tx";
				compatible = "xlnx,dp-snd-pcm1";
				status = "okay";
				phandle = <0x23>;
				dmas = <0x20 0x05>;
			};
		};

		dma@ffac0000 {
			power-domains = <0x0c 0x2b>;
			clock-names = "clk_main\0clk_apb";
			interrupts = <0x00 0x51 0x04>;
			clocks = <0x03 0x44 0x03 0x1f>;
			interrupt-parent = <0x04>;
			xlnx,bus-width = <0x40>;
			compatible = "xlnx,zynqmp-dma-1.0";
			status = "okay";
			#stream-id-cells = <0x01>;
			reg = <0x00 0xffac0000 0x00 0x1000>;
			phandle = <0x54>;
		};

		smmu@fd800000 {
			#global-interrupts = <0x01>;
			interrupts = <0x00 0x9b 0x04 0x00 0x9b 0x04 0x00 0x9b 0x04 0x00 0x9b 0x04 0x00 0x9b 0x04 0x00 0x9b 0x04 0x00 0x9b 0x04 0x00 0x9b 0x04 0x00 0x9b 0x04 0x00 0x9b 0x04 0x00 0x9b 0x04 0x00 0x9b 0x04 0x00 0x9b 0x04 0x00 0x9b 0x04 0x00 0x9b 0x04 0x00 0x9b 0x04 0x00 0x9b 0x04>;
			interrupt-parent = <0x04>;
			#iommu-cells = <0x01>;
			compatible = "arm,mmu-500";
			status = "disabled";
			reg = <0x00 0xfd800000 0x00 0x20000>;
			phandle = <0x0e>;
		};

		timer@ff120000 {
			power-domains = <0x0c 0x19>;
			timer-width = <0x20>;
			interrupts = <0x00 0x27 0x04 0x00 0x28 0x04 0x00 0x29 0x04>;
			clocks = <0x03 0x1f>;
			interrupt-parent = <0x04>;
			compatible = "cdns,ttc";
			status = "disabled";
			reg = <0x00 0xff120000 0x00 0x1000>;
			phandle = <0x72>;
		};

		watchdog@ff150000 {
			interrupts = <0x00 0x34 0x01>;
			clocks = <0x03 0x70>;
			interrupt-parent = <0x04>;
			timeout-sec = <0x0a>;
			compatible = "cdns,wdt-r1p2";
			status = "okay";
			reg = <0x00 0xff150000 0x00 0x1000>;
			phandle = <0x7c>;
		};

		ethernet@ff0c0000 {
			power-domains = <0x0c 0x1e>;
			iommus = <0x0e 0x875>;
			#address-cells = <0x01>;
			clock-names = "pclk\0hclk\0tx_clk\0rx_clk\0tsu_clk";
			interrupts = <0x00 0x3b 0x04 0x00 0x3b 0x04>;
			clocks = <0x03 0x1f 0x03 0x69 0x03 0x2e 0x03 0x32 0x03 0x2c>;
			#size-cells = <0x00>;
			interrupt-parent = <0x04>;
			compatible = "cdns,zynqmp-gem\0cdns,gem";
			status = "disabled";
			#stream-id-cells = <0x01>;
			reg = <0x00 0xff0c0000 0x00 0x1000>;
			phandle = <0x5b>;
		};

		can@ff060000 {
			power-domains = <0x0c 0x2f>;
			clock-names = "can_clk\0pclk";
			interrupts = <0x00 0x17 0x04>;
			clocks = <0x03 0x3f 0x03 0x1f>;
			interrupt-parent = <0x04>;
			compatible = "xlnx,zynq-can-1.0";
			status = "disabled";
			tx-fifo-depth = <0x40>;
			rx-fifo-depth = <0x40>;
			reg = <0x00 0xff060000 0x00 0x1000>;
			phandle = <0x44>;
		};

		dma@fd520000 {
			power-domains = <0x0c 0x2a>;
			iommus = <0x0e 0x14ea>;
			clock-names = "clk_main\0clk_apb";
			interrupts = <0x00 0x7e 0x04>;
			clocks = <0x03 0x13 0x03 0x1f>;
			interrupt-parent = <0x04>;
			xlnx,bus-width = <0x80>;
			compatible = "generic-uio";
			status = "okay";
			#stream-id-cells = <0x01>;
			reg = <0x00 0xfd520000 0x00 0x1000>;
			phandle = <0x49>;
		};

		dma@ffa90000 {
			power-domains = <0x0c 0x2b>;
			clock-names = "clk_main\0clk_apb";
			interrupts = <0x00 0x4e 0x04>;
			clocks = <0x03 0x44 0x03 0x1f>;
			interrupt-parent = <0x04>;
			xlnx,bus-width = <0x40>;
			compatible = "xlnx,zynqmp-dma-1.0";
			status = "okay";
			#stream-id-cells = <0x01>;
			reg = <0x00 0xffa90000 0x00 0x1000>;
			phandle = <0x51>;
		};

		dma@fd560000 {
			power-domains = <0x0c 0x2a>;
			iommus = <0x0e 0x14ee>;
			clock-names = "clk_main\0clk_apb";
			interrupts = <0x00 0x82 0x04>;
			clocks = <0x03 0x13 0x03 0x1f>;
			interrupt-parent = <0x04>;
			xlnx,bus-width = <0x80>;
			compatible = "generic-uio";
			status = "okay";
			#stream-id-cells = <0x01>;
			reg = <0x00 0xfd560000 0x00 0x1000>;
			phandle = <0x4d>;
		};

		perf-monitor@ffa00000 {
			xlnx,metric-count-width = <0x20>;
			xlnx,have-sampled-metric-cnt = <0x01>;
			xlnx,enable-trace = <0x00>;
			xlnx,global-count-width = <0x20>;
			xlnx,enable-event-count = <0x01>;
			interrupts = <0x00 0x19 0x04>;
			clocks = <0x03 0x1f>;
			xlnx,enable-profile = <0x00>;
			xlnx,metric-count-scale = <0x01>;
			interrupt-parent = <0x04>;
			xlnx,num-monitor-slots = <0x01>;
			compatible = "xlnx,axi-perf-monitor";
			xlnx,num-of-counters = <0x08>;
			reg = <0x00 0xffa00000 0x00 0x10000>;
			phandle = <0x65>;
			xlnx,metrics-sample-count-width = <0x20>;
			xlnx,enable-event-log = <0x01>;
		};

		gpu@fd4b0000 {
			power-domains = <0x0c 0x3a>;
			xlnx,tz-nonsecure = <0x01>;
			clock-names = "gpu\0gpu_pp0\0gpu_pp1";
			interrupts = <0x00 0x84 0x04 0x00 0x84 0x04 0x00 0x84 0x04 0x00 0x84 0x04 0x00 0x84 0x04 0x00 0x84 0x04>;
			clocks = <0x03 0x18 0x03 0x19 0x03 0x1a>;
			interrupt-parent = <0x04>;
			compatible = "arm,mali-400\0arm,mali-utgard";
			status = "okay";
			interrupt-names = "IRQGP\0IRQGPMMU\0IRQPP0\0IRQPPMMU0\0IRQPP1\0IRQPPMMU1";
			reg = <0x00 0xfd4b0000 0x00 0x10000>;
			phandle = <0x4f>;
		};

		serial@ff000000 {
			power-domains = <0x0c 0x21>;
			pinctrl-names = "default";
			pinctrl-0 = <0x1c>;
			clock-names = "uart_clk\0pclk";
			u-boot,dm-pre-reloc;
			cts-override;
			interrupts = <0x00 0x15 0x04>;
			clocks = <0x03 0x38 0x03 0x1f>;
			interrupt-parent = <0x04>;
			device_type = "serial";
			port-number = <0x00>;
			compatible = "cdns,uart-r1p12\0xlnx,xuartps";
			status = "okay";
			reg = <0x00 0xff000000 0x00 0x1000>;
			phandle = <0x75>;
		};

		i2c@ff030000 {
			power-domains = <0x0c 0x26>;
			pinctrl-names = "default\0gpio";
			#address-cells = <0x01>;
			pinctrl-0 = <0x11>;
			interrupts = <0x00 0x12 0x04>;
			clocks = <0x03 0x3e>;
			#size-cells = <0x00>;
			interrupt-parent = <0x04>;
			clock-frequency = <0x61a80>;
			compatible = "cdns,i2c-r1p14";
			pinctrl-1 = <0x12>;
			status = "okay";
			reg = <0x00 0xff030000 0x00 0x1000>;
			phandle = <0x5f>;
			scl-gpios = <0x13 0x10 0x00>;
			sda-gpios = <0x13 0x11 0x00>;

			gpio@20 {
				gpio-controller;
				compatible = "ti,tca6416";
				reg = <0x20>;
				phandle = <0x60>;
				#gpio-cells = <0x02>;
			};

			i2c-mux@74 {
				#address-cells = <0x01>;
				#size-cells = <0x00>;
				compatible = "nxp,pca9548";
				reg = <0x74>;

				i2c@0 {
					#address-cells = <0x01>;
					#size-cells = <0x00>;
					reg = <0x00>;

					eeprom@54 {
						#address-cells = <0x01>;
						#size-cells = <0x01>;
						compatible = "atmel,24c08";
						reg = <0x54>;
						phandle = <0x61>;
					};
				};

				i2c@7 {
					#address-cells = <0x01>;
					#size-cells = <0x00>;
					reg = <0x07>;
				};

				i2c@5 {
					#address-cells = <0x01>;
					#size-cells = <0x00>;
					reg = <0x05>;
				};

				i2c@3 {
					#address-cells = <0x01>;
					#size-cells = <0x00>;
					reg = <0x03>;

					ina226@40 {
						#io-channel-cells = <0x01>;
						compatible = "ti,ina226";
						reg = <0x40>;
						phandle = <0x25>;
						shunt-resistor = <0x1388>;
					};
				};

				i2c@1 {
					#address-cells = <0x01>;
					#size-cells = <0x00>;
					reg = <0x01>;
				};

				i2c@2 {
					#address-cells = <0x01>;
					#size-cells = <0x00>;
					reg = <0x02>;

					irps5401@43 {
						compatible = "infineon,irps5401";
						reg = <0x43>;
						phandle = <0x62>;
					};

					irps5401@44 {
						compatible = "infineon,irps5401";
						reg = <0x44>;
						phandle = <0x63>;
					};
				};
			};
		};

		watchdog@fd4d0000 {
			interrupts = <0x00 0x71 0x01>;
			clocks = <0x03 0x4b>;
			interrupt-parent = <0x04>;
			timeout-sec = <0x3c>;
			reset-on-timeout;
			compatible = "cdns,wdt-r1p2";
			status = "okay";
			reg = <0x00 0xfd4d0000 0x00 0x1000>;
			phandle = <0x7b>;
		};

		dma@ffad0000 {
			power-domains = <0x0c 0x2b>;
			clock-names = "clk_main\0clk_apb";
			interrupts = <0x00 0x52 0x04>;
			clocks = <0x03 0x44 0x03 0x1f>;
			interrupt-parent = <0x04>;
			xlnx,bus-width = <0x40>;
			compatible = "xlnx,zynqmp-dma-1.0";
			status = "okay";
			#stream-id-cells = <0x01>;
			reg = <0x00 0xffad0000 0x00 0x1000>;
			phandle = <0x55>;
		};

		phy@fd400000 {
			clock-names = "ref1\0ref2\0ref3";
			reg-names = "serdes\0siou";
			clocks = <0x16 0x17 0x18>;
			#phy-cells = <0x04>;
			compatible = "xlnx,zynqmp-psgtr-v1.1";
			status = "okay";
			reg = <0x00 0xfd400000 0x00 0x40000 0x00 0xfd3d0000 0x00 0x1000>;
			phandle = <0x1a>;
		};

		spi@ff0f0000 {
			power-domains = <0x0c 0x2d>;
			iommus = <0x0e 0x873>;
			#address-cells = <0x01>;
			num-cs = <0x01>;
			clock-names = "ref_clk\0pclk";
			spi-tx-bus-width = <0x04>;
			u-boot,dm-pre-reloc;
			is-dual = <0x00>;
			interrupts = <0x00 0x0f 0x04>;
			clocks = <0x03 0x35 0x03 0x1f>;
			#size-cells = <0x00>;
			spi-rx-bus-width = <0x04>;
			interrupt-parent = <0x04>;
			compatible = "xlnx,zynqmp-qspi-1.0";
			status = "okay";
			#stream-id-cells = <0x01>;
			reg = <0x00 0xff0f0000 0x00 0x1000 0x00 0xc0000000 0x00 0x8000000>;
			phandle = <0x69>;

			flash@0 {
				#address-cells = <0x01>;
				spi-tx-bus-width = <0x01>;
				#size-cells = <0x01>;
				spi-max-frequency = <0x66ff300>;
				spi-rx-bus-width = <0x04>;
				compatible = "m25p80\0jedec,spi-nor";
				reg = <0x00>;
				phandle = <0x6a>;

				partition@2 {
					label = "kernel";
					reg = <0x140000 0x1600000>;
				};

				partition@0 {
					label = "boot";
					reg = <0x00 0x100000>;
				};

				partition@1 {
					label = "bootenv";
					reg = <0x100000 0x40000>;
				};
			};
		};

		timer@ff130000 {
			power-domains = <0x0c 0x1a>;
			timer-width = <0x20>;
			interrupts = <0x00 0x2a 0x04 0x00 0x2b 0x04 0x00 0x2c 0x04>;
			clocks = <0x03 0x1f>;
			interrupt-parent = <0x04>;
			compatible = "cdns,ttc";
			status = "disabled";
			reg = <0x00 0xff130000 0x00 0x1000>;
			phandle = <0x73>;
		};

		usb1@ff9e0000 {
			power-domains = <0x0c 0x17>;
			#address-cells = <0x02>;
			clock-names = "bus_clk\0ref_clk";
			resets = <0x19 0x3c 0x19 0x3e 0x19 0x40>;
			clocks = <0x03 0x21 0x03 0x22>;
			#size-cells = <0x02>;
			compatible = "xlnx,zynqmp-dwc3";
			ranges;
			status = "disabled";
			reg = <0x00 0xff9e0000 0x00 0x100>;
			phandle = <0x79>;
			reset-names = "usb_crst\0usb_hibrst\0usb_apbrst";

			dwc3@fe300000 {
				iommus = <0x0e 0x861>;
				snps,quirk-frame-length-adjustment = <0x20>;
				snps,refclk_fladj;
				interrupts = <0x00 0x46 0x04 0x00 0x4a 0x04 0x00 0x4c 0x04>;
				interrupt-parent = <0x04>;
				compatible = "snps,dwc3";
				status = "disabled";
				interrupt-names = "dwc_usb3\0otg\0hiber";
				snps,enable_guctl1_ipd_quirk;
				#stream-id-cells = <0x01>;
				snps,xhci-stream-quirk;
				reg = <0x00 0xfe300000 0x00 0x40000>;
				phandle = <0x7a>;
				snps,enable_guctl1_resume_quirk;
			};
		};

		spi@ff040000 {
			power-domains = <0x0c 0x23>;
			#address-cells = <0x01>;
			clock-names = "ref_clk\0pclk";
			interrupts = <0x00 0x13 0x04>;
			clocks = <0x03 0x3a 0x03 0x1f>;
			#size-cells = <0x00>;
			interrupt-parent = <0x04>;
			compatible = "cdns,spi-r1p6";
			status = "disabled";
			reg = <0x00 0xff040000 0x00 0x1000>;
			phandle = <0x6f>;
		};

		ethernet@ff0d0000 {
			power-domains = <0x0c 0x1f>;
			iommus = <0x0e 0x876>;
			#address-cells = <0x01>;
			clock-names = "pclk\0hclk\0tx_clk\0rx_clk\0tsu_clk";
			interrupts = <0x00 0x3d 0x04 0x00 0x3d 0x04>;
			clocks = <0x03 0x1f 0x03 0x6a 0x03 0x2f 0x03 0x33 0x03 0x2c>;
			#size-cells = <0x00>;
			interrupt-parent = <0x04>;
			compatible = "cdns,zynqmp-gem\0cdns,gem";
			status = "disabled";
			#stream-id-cells = <0x01>;
			reg = <0x00 0xff0d0000 0x00 0x1000>;
			phandle = <0x5c>;
		};

		can@ff070000 {
			power-domains = <0x0c 0x30>;
			pinctrl-names = "default";
			pinctrl-0 = <0x0d>;
			clock-names = "can_clk\0pclk";
			interrupts = <0x00 0x18 0x04>;
			clocks = <0x03 0x40 0x03 0x1f>;
			interrupt-parent = <0x04>;
			compatible = "xlnx,zynq-can-1.0";
			status = "okay";
			tx-fifo-depth = <0x40>;
			rx-fifo-depth = <0x40>;
			reg = <0x00 0xff070000 0x00 0x1000>;
			phandle = <0x45>;
		};

		dma@fd530000 {
			power-domains = <0x0c 0x2a>;
			iommus = <0x0e 0x14eb>;
			clock-names = "clk_main\0clk_apb";
			interrupts = <0x00 0x7f 0x04>;
			clocks = <0x03 0x13 0x03 0x1f>;
			interrupt-parent = <0x04>;
			xlnx,bus-width = <0x80>;
			compatible = "generic-uio";
			status = "okay";
			#stream-id-cells = <0x01>;
			reg = <0x00 0xfd530000 0x00 0x1000>;
			phandle = <0x4a>;
		};

		dma@fd570000 {
			power-domains = <0x0c 0x2a>;
			iommus = <0x0e 0x14ef>;
			clock-names = "clk_main\0clk_apb";
			interrupts = <0x00 0x83 0x04>;
			clocks = <0x03 0x13 0x03 0x1f>;
			interrupt-parent = <0x04>;
			xlnx,bus-width = <0x80>;
			compatible = "generic-uio";
			status = "okay";
			#stream-id-cells = <0x01>;
			reg = <0x00 0xfd570000 0x00 0x1000>;
			phandle = <0x4e>;
		};

		perf-monitor@ffa10000 {
			xlnx,metric-count-width = <0x20>;
			xlnx,have-sampled-metric-cnt = <0x01>;
			xlnx,enable-trace = <0x00>;
			xlnx,global-count-width = <0x20>;
			xlnx,enable-event-count = <0x01>;
			interrupts = <0x00 0x19 0x04>;
			clocks = <0x03 0x1f>;
			xlnx,enable-profile = <0x00>;
			xlnx,metric-count-scale = <0x01>;
			interrupt-parent = <0x04>;
			xlnx,num-monitor-slots = <0x01>;
			compatible = "xlnx,axi-perf-monitor";
			xlnx,num-of-counters = <0x08>;
			reg = <0x00 0xffa10000 0x00 0x10000>;
			phandle = <0x68>;
			xlnx,metrics-sample-count-width = <0x20>;
			xlnx,enable-event-log = <0x01>;
		};

		mmc@ff160000 {
			power-domains = <0x0c 0x27>;
			iommus = <0x0e 0x870>;
			clock-output-names = "clk_out_sd0\0clk_in_sd0";
			clock-names = "clk_xin\0clk_ahb";
			u-boot,dm-pre-reloc;
			interrupts = <0x00 0x30 0x04>;
			clocks = <0x03 0x36 0x03 0x1f>;
			#clock-cells = <0x01>;
			xlnx,device_id = <0x00>;
			interrupt-parent = <0x04>;
			compatible = "xlnx,zynqmp-8.9a\0arasan,sdhci-8.9a";
			status = "disabled";
			#stream-id-cells = <0x01>;
			reg = <0x00 0xff160000 0x00 0x1000>;
			phandle = <0x6d>;
		};

		perf-monitor@fd490000 {
			xlnx,metric-count-width = <0x20>;
			xlnx,have-sampled-metric-cnt = <0x01>;
			xlnx,enable-trace = <0x00>;
			xlnx,global-count-width = <0x20>;
			xlnx,enable-event-count = <0x01>;
			interrupts = <0x00 0x7b 0x04>;
			clocks = <0x03 0x1c>;
			xlnx,enable-profile = <0x00>;
			xlnx,metric-count-scale = <0x01>;
			interrupt-parent = <0x04>;
			xlnx,num-monitor-slots = <0x01>;
			compatible = "xlnx,axi-perf-monitor";
			xlnx,num-of-counters = <0x08>;
			reg = <0x00 0xfd490000 0x00 0x10000>;
			phandle = <0x67>;
			xlnx,metrics-sample-count-width = <0x20>;
			xlnx,enable-event-log = <0x00>;
		};

		serial@ff010000 {
			power-domains = <0x0c 0x22>;
			pinctrl-names = "default";
			pinctrl-0 = <0x1d>;
			clock-names = "uart_clk\0pclk";
			u-boot,dm-pre-reloc;
			cts-override;
			interrupts = <0x00 0x16 0x04>;
			clocks = <0x03 0x39 0x03 0x1f>;
			interrupt-parent = <0x04>;
			device_type = "serial";
			port-number = <0x01>;
			compatible = "cdns,uart-r1p12\0xlnx,xuartps";
			status = "okay";
			reg = <0x00 0xff010000 0x00 0x1000>;
			phandle = <0x76>;
		};

		ahci@fd0c0000 {
			power-domains = <0x0c 0x1c>;
			ceva,p0-comwake-params = <0x614080e>;
			phy-names = "sata-phy";
			ceva,p0-retry-params = <0x96a43ffc>;
			ceva,p0-burst-params = <0x13084a06>;
			resets = <0x19 0x10>;
			interrupts = <0x00 0x85 0x04>;
			clocks = <0x03 0x16>;
			interrupt-parent = <0x04>;
			xlnx,tz-nonsecure-sata0 = <0x00>;
			ceva,p1-retry-params = <0x96a43ffc>;
			ceva,p1-burst-params = <0x13084a06>;
			ceva,p1-cominit-params = <0x18401828>;
			compatible = "ceva,ahci-1v84";
			status = "okay";
			phys = <0x1a 0x03 0x01 0x01 0x01>;
			#stream-id-cells = <0x04>;
			reg = <0x00 0xfd0c0000 0x00 0x2000>;
			phandle = <0x6c>;
			ceva,p0-cominit-params = <0x18401828>;
			xlnx,tz-nonsecure-sata1 = <0x00>;
			ceva,p1-comwake-params = <0x614080e>;
		};

		dma@ffaa0000 {
			power-domains = <0x0c 0x2b>;
			clock-names = "clk_main\0clk_apb";
			interrupts = <0x00 0x4f 0x04>;
			clocks = <0x03 0x44 0x03 0x1f>;
			interrupt-parent = <0x04>;
			xlnx,bus-width = <0x40>;
			compatible = "xlnx,zynqmp-dma-1.0";
			status = "okay";
			#stream-id-cells = <0x01>;
			reg = <0x00 0xffaa0000 0x00 0x1000>;
			phandle = <0x52>;
		};

		cci@fd6e0000 {
			#address-cells = <0x01>;
			#size-cells = <0x01>;
			compatible = "arm,cci-400";
			ranges = <0x00 0x00 0xfd6e0000 0x10000>;
			status = "okay";
			reg = <0x00 0xfd6e0000 0x00 0x9000>;
			phandle = <0x46>;

			pmu@9000 {
				interrupts = <0x00 0x7b 0x04 0x00 0x7b 0x04 0x00 0x7b 0x04 0x00 0x7b 0x04 0x00 0x7b 0x04>;
				interrupt-parent = <0x04>;
				compatible = "arm,cci-400-pmu,r1";
				reg = <0x9000 0x5000>;
			};
		};

		pcie@fd0e0000 {
			power-domains = <0x0c 0x3b>;
			iommus = <0x0e 0x4d0>;
			#address-cells = <0x03>;
			bus-range = <0x00 0xff>;
			reg-names = "breg\0pcireg\0cfg";
			interrupts = <0x00 0x76 0x04 0x00 0x75 0x04 0x00 0x74 0x04 0x00 0x73 0x04 0x00 0x72 0x04>;
			clocks = <0x03 0x17>;
			interrupt-map = <0x00 0x00 0x00 0x01 0x15 0x01 0x00 0x00 0x00 0x02 0x15 0x02 0x00 0x00 0x00 0x03 0x15 0x03 0x00 0x00 0x00 0x04 0x15 0x04>;
			#size-cells = <0x02>;
			interrupt-parent = <0x04>;
			msi-controller;
			device_type = "pci";
			interrupt-map-mask = <0x00 0x00 0x00 0x07>;
			compatible = "xlnx,nwl-pcie-2.11";
			ranges = <0x2000000 0x00 0xe0000000 0x00 0xe0000000 0x00 0x10000000 0x43000000 0x06 0x00 0x06 0x00 0x02 0x00>;
			#interrupt-cells = <0x01>;
			status = "disabled";
			interrupt-names = "misc\0dummy\0intx\0msi1\0msi0";
			#stream-id-cells = <0x01>;
			reg = <0x00 0xfd0e0000 0x00 0x1000 0x00 0xfd480000 0x00 0x1000 0x80 0x00 0x00 0x1000000>;
			phandle = <0x14>;
			msi-parent = <0x14>;

			legacy-interrupt-controller {
				#address-cells = <0x00>;
				#interrupt-cells = <0x01>;
				phandle = <0x15>;
				interrupt-controller;
			};
		};

		dma@ffae0000 {
			power-domains = <0x0c 0x2b>;
			clock-names = "clk_main\0clk_apb";
			interrupts = <0x00 0x53 0x04>;
			clocks = <0x03 0x44 0x03 0x1f>;
			interrupt-parent = <0x04>;
			xlnx,bus-width = <0x40>;
			compatible = "xlnx,zynqmp-dma-1.0";
			status = "okay";
			#stream-id-cells = <0x01>;
			reg = <0x00 0xffae0000 0x00 0x1000>;
			phandle = <0x56>;
		};
	};

	amba_pl@0 {
		#address-cells = <0x02>;
		#size-cells = <0x02>;
		compatible = "simple-bus";
		ranges;
		phandle = <0x86>;

		CGRA@400000000 {
			xlnx,s00-axi-ruser-width = <0x00>;
			xlnx,s00-axi-wuser-width = <0x00>;
			clock-names = "s00_axi_aclk";
			clocks = <0x03 0x47>;
			xlnx,s00-axi-aruser-width = <0x10>;
			xlnx,s00-axi-awuser-width = <0x10>;
			xlnx,s00-axi-data-width = <0x20>;
			compatible = "generic-uio";
			reg = <0x04 0x00 0x01 0x00>;
			phandle = <0x87>;
			xlnx,s00-axi-id-width = <0x00>;
			xlnx,s00-axi-buser-width = <0x00>;
			xlnx,s00-axi-addr-width = <0x06>;
		};
	};

	memory {
		device_type = "memory";
		reg = <0x00 0x00 0x00 0x7ff00000>;
	};
};
